# HC32F558 register map
File version: 1.0
CPU: CM4 r0p1, little endian, MPU, FPU, 4 interrupt priority bits
Registers are 32-bit, read-write, reset 0x0 unless marked. A register's access mark holds for its fields unless they carry their own. Offsets are from the block's base; [hi:lo] are bit positions; {n}, {i} and the like mark numbered series.

## AOS
Base 0x40010800
0x00 INTSFTTRG wo
  [0] STRG
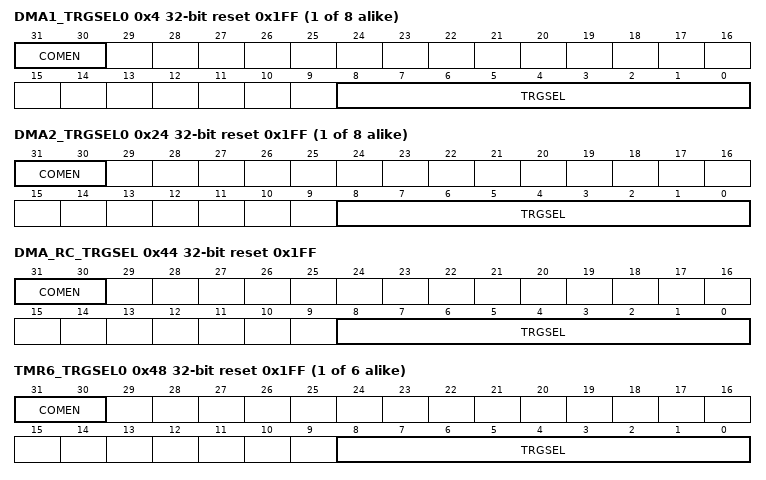
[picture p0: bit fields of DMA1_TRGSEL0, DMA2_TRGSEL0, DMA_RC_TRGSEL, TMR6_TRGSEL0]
{0x4+4i} DMA1_TRGSEL{i} reset 0x1FF (i=0..7)
  [31:30] COMEN, [8:0] TRGSEL
{0x24+4i} DMA2_TRGSEL{i} reset 0x1FF (i=0..7)
  [31:30] COMEN, [8:0] TRGSEL
0x44 DMA_RC_TRGSEL reset 0x1FF
  [31:30] COMEN, [8:0] TRGSEL
{0x48+4i} TMR6_TRGSEL{i} reset 0x1FF (i=0..5)
  [31:30] COMEN, [8:0] TRGSEL
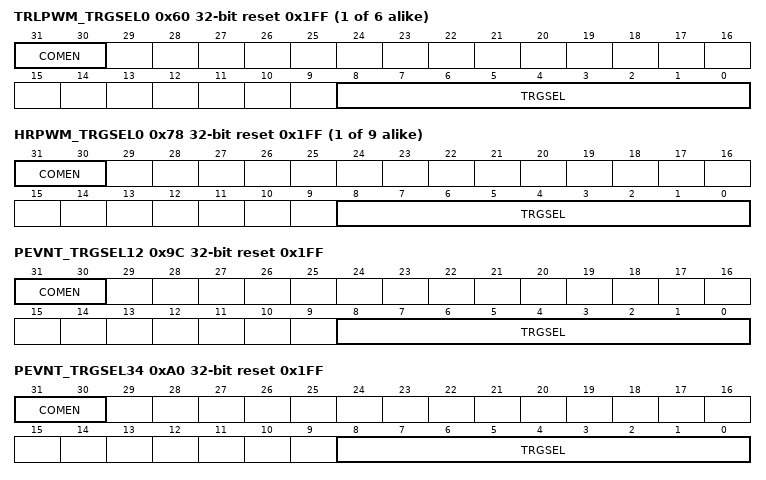
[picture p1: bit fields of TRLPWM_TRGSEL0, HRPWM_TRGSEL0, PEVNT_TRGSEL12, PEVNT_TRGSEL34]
{0x60+4i} TRLPWM_TRGSEL{i} reset 0x1FF (i=0..5)
  [31:30] COMEN, [8:0] TRGSEL
{0x78+4i} HRPWM_TRGSEL{i} reset 0x1FF (i=0..8)
  [31:30] COMEN, [8:0] TRGSEL
0x9C PEVNT_TRGSEL12 reset 0x1FF
  [31:30] COMEN, [8:0] TRGSEL
0xA0 PEVNT_TRGSEL34 reset 0x1FF
  [31:30] COMEN, [8:0] TRGSEL
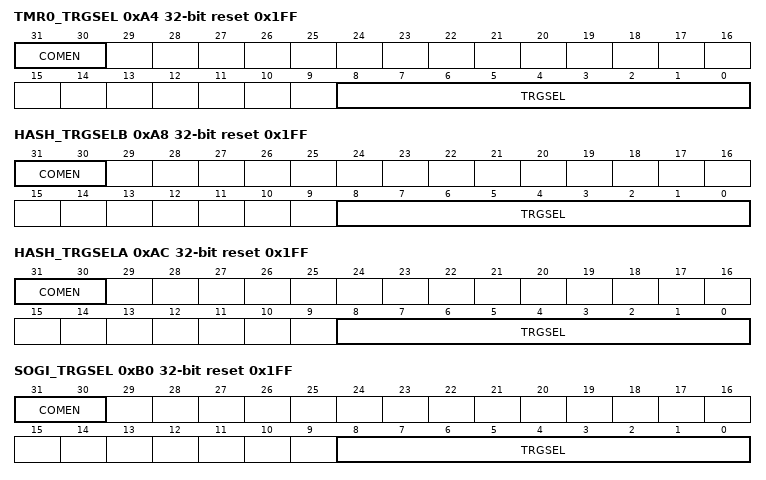
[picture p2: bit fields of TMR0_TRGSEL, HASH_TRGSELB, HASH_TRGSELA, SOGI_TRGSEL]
0xA4 TMR0_TRGSEL reset 0x1FF
  [31:30] COMEN, [8:0] TRGSEL
0xA8 HASH_TRGSELB reset 0x1FF
  [31:30] COMEN, [8:0] TRGSEL
0xAC HASH_TRGSELA reset 0x1FF
  [31:30] COMEN, [8:0] TRGSEL
0xB0 SOGI_TRGSEL reset 0x1FF
  [31:30] COMEN, [8:0] TRGSEL
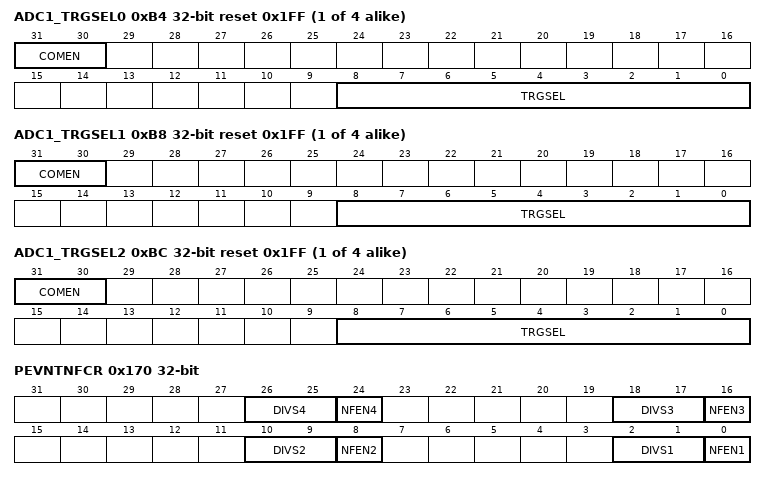
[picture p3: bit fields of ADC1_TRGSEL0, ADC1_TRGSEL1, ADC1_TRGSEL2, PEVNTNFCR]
{0xA8+0xC*i} ADC{i}_TRGSEL0 reset 0x1FF (i=1..4)
  [31:30] COMEN, [8:0] TRGSEL
{0xAC+0xC*i} ADC{i}_TRGSEL1 reset 0x1FF (i=1..4)
  [31:30] COMEN, [8:0] TRGSEL
{0xB0+0xC*i} ADC{i}_TRGSEL2 reset 0x1FF (i=1..4)
  [31:30] COMEN, [8:0] TRGSEL
0xE4 COMTRGSEL1 reset 0x1FF
  [8:0] COMTRG
0xE8 COMTRGSEL2 reset 0x1FF
  [8:0] COMTRG
{0xE4+0x1C*i} PEVNTDIRR{i} (i=1..4)
  [15:0] PDIR
{0xE8+0x1C*i} PEVNTIDR{i} ro (i=1..4)
  [15:0] PIN
{0xEC+0x1C*i} PEVNTODR{i} (i=1..4)
  [15:0] POUT
{0xF0+0x1C*i} PEVNTORR{i} (i=1..4)
  [15:0] POR
{0xF4+0x1C*i} PEVNTOSR{i} (i=1..4)
  [15:0] POS
{0xF8+0x1C*i} PEVNTRISR{i} (i=1..4)
  [15:0] RIS
{0xFC+0x1C*i} PEVNTFALR{i} (i=1..4)
  [15:0] FAL
0x170 PEVNTNFCR
  [8n-6:8n-7] DIVS{n} (n=1..4), [8n-8] NFEN{n} (n=1..4)

## CMP1
Base 0x4003B000
Same registers: CMP3 0x4003B200, CMP5 0x4003B400, CMP7 0x4003B600
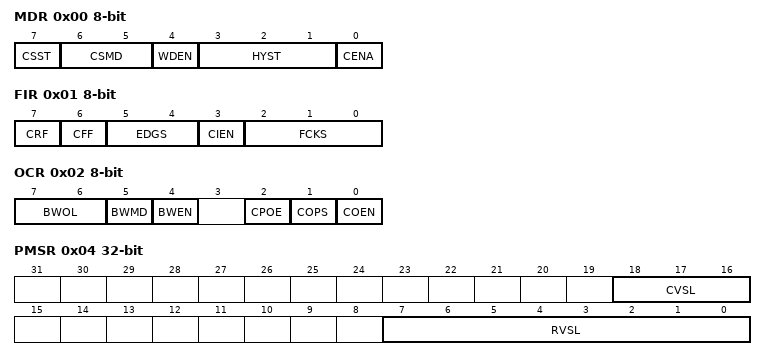
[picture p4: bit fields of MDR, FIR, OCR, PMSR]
0x00 MDR 8-bit
  [7] CSST, [6:5] CSMD, [4] WDEN, [3:1] HYST, [0] CENA
0x01 FIR 8-bit
  [7] CRF, [6] CFF, [5:4] EDGS, [3] CIEN, [2:0] FCKS
0x02 OCR 8-bit
  [7:6] BWOL, [5] BWMD, [4] BWEN, [2] CPOE, [1] COPS, [0] COEN
0x03 OMR 8-bit ro
  [0] CMON
0x04 PMSR
  [18:16] CVSL, [7:0] RVSL
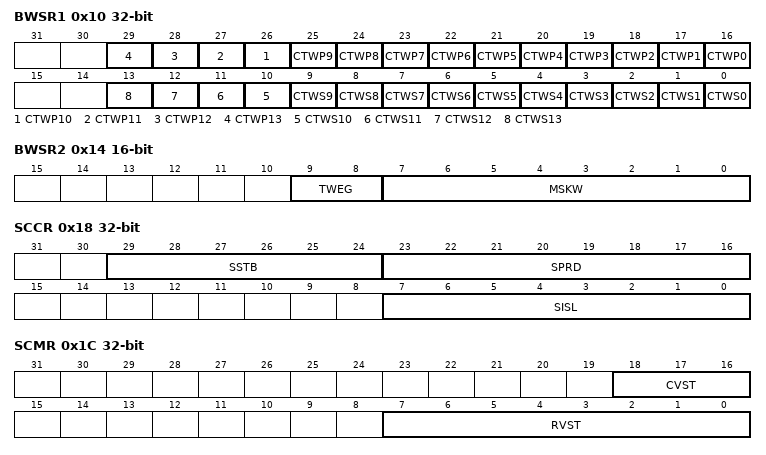
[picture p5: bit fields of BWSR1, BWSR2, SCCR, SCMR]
0x10 BWSR1
  [n+16] CTWP{n} (n=0..13), [n] CTWS{n} (n=0..13)
0x14 BWSR2 16-bit
  [9:8] TWEG, [7:0] MSKW
0x18 SCCR
  [29:24] SSTB, [23:16] SPRD, [7:0] SISL
0x1C SCMR
  [18:16] CVST, [7:0] RVST

## CMP2
Base 0x4003B100
Same registers: CMP4 0x4003B300, CMP6 0x4003B500, CMP8 0x4003B700
Registers as CMP1; these are added or differ:
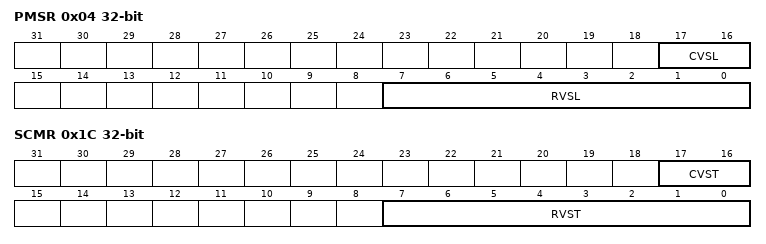
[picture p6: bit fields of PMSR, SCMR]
0x04 PMSR
  [17:16] CVSL, [7:0] RVSL
0x1C SCMR
  [17:16] CVST, [7:0] RVST

## CMU
Base 0x40048000
0x4C6C LRCCR 8-bit
  [0] LRCSTP
0x4C74 LRCTRM 8-bit
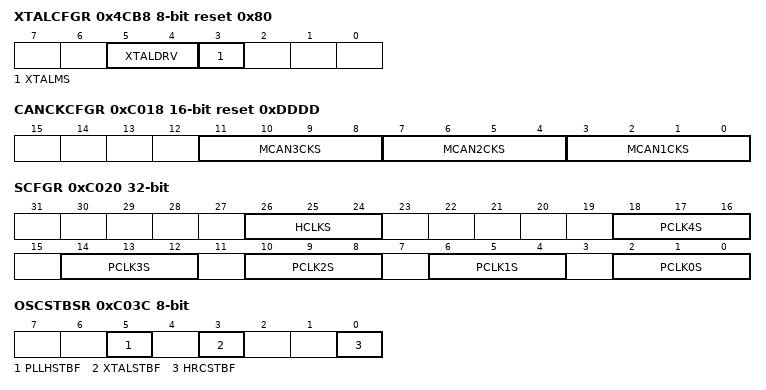
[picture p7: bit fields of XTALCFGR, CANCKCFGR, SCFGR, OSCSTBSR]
0x4CB8 XTALCFGR 8-bit reset 0x80
  [5:4] XTALDRV, [3] XTALMS
0xC010 PERICKSEL 16-bit
  [3:0] PERICKSEL
0xC018 CANCKCFGR 16-bit reset 0xDDDD
  [11:8] MCAN3CKS, [7:4] MCAN2CKS, [3:0] MCAN1CKS
0xC020 SCFGR
  [26:24] HCLKS, [4n+2:4n] PCLK{n}S (n=0..4)
0xC026 CKSWR 8-bit reset 0x1
  [2:0] CKSW
0xC02A PLLHCR 8-bit reset 0x1
  [0] PLLHOFF
0xC032 XTALCR 8-bit reset 0x1
  [0] XTALSTP
0xC036 HRCCR 8-bit reset 0x1
  [0] HRCSTP
0xC038 MRCCR 8-bit reset 0x80
  [0] MRCSTP
0xC03C OSCSTBSR 8-bit ro
  [5] PLLHSTBF, [3] XTALSTBF, [0] HRCSTBF
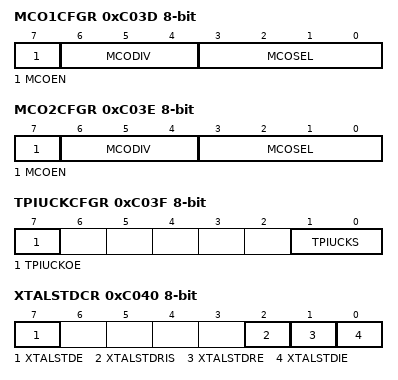
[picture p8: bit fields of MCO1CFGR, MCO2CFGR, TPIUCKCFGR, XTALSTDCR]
0xC03D MCO1CFGR 8-bit
  [7] MCOEN, [6:4] MCODIV, [3:0] MCOSEL
0xC03E MCO2CFGR 8-bit
  [7] MCOEN, [6:4] MCODIV, [3:0] MCOSEL
0xC03F TPIUCKCFGR 8-bit
  [7] TPIUCKOE, [1:0] TPIUCKS
0xC040 XTALSTDCR 8-bit
  [7] XTALSTDE, [2] XTALSTDRIS, [1] XTALSTDRE, [0] XTALSTDIE
0xC041 XTALSTDSR 8-bit
  [0] XTALSTDF
0xC060 MRCTRM 16-bit (reset mask 0x1FF)
0xC062 HRCTRM 8-bit
0xC0A2 XTALSTBCR 8-bit reset 0x5
  [3:0] XTALSTB
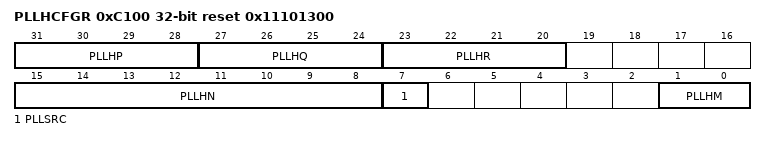
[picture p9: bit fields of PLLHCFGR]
0xC100 PLLHCFGR reset 0x11101300
  [31:28] PLLHP, [27:24] PLLHQ, [23:20] PLLHR, [15:8] PLLHN, [7] PLLSRC, [1:0] PLLHM

## CORDIC
Base 0x40055000
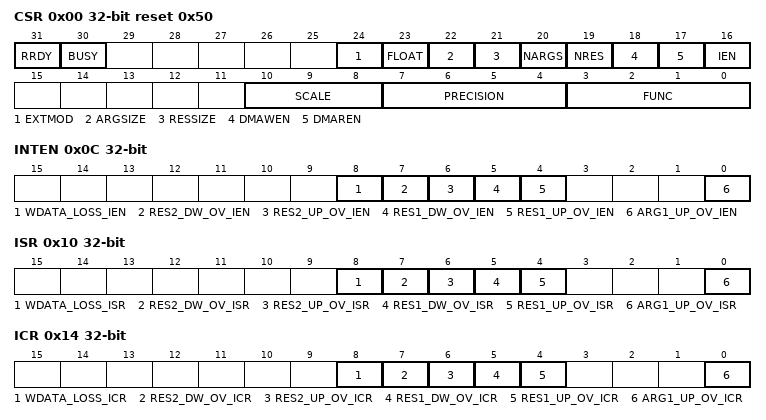
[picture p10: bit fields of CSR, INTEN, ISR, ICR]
0x00 CSR reset 0x50
  [31] RRDY ro, [30] BUSY ro, [24] EXTMOD, [23] FLOAT, [22] ARGSIZE, [21] RESSIZE, [20] NARGS, [19] NRES, [18] DMAWEN, [17] DMAREN, [16] IEN, [10:8] SCALE, [7:4] PRECISION, [3:0] FUNC
0x04 WDATA wo
0x08 RDATA ro
0x0C INTEN
  [8] WDATA_LOSS_IEN, [7] RES2_DW_OV_IEN, [6] RES2_UP_OV_IEN, [5] RES1_DW_OV_IEN, [4] RES1_UP_OV_IEN, [0] ARG1_UP_OV_IEN
0x10 ISR
  [8] WDATA_LOSS_ISR, [7] RES2_DW_OV_ISR ro, [6] RES2_UP_OV_ISR ro, [5] RES1_DW_OV_ISR ro, [4] RES1_UP_OV_ISR ro, [0] ARG1_UP_OV_ISR ro
0x14 ICR wo
  [8] WDATA_LOSS_ICR, [7] RES2_DW_OV_ICR, [6] RES2_UP_OV_ICR, [5] RES1_DW_OV_ICR, [4] RES1_UP_OV_ICR, [0] ARG1_UP_OV_ICR
